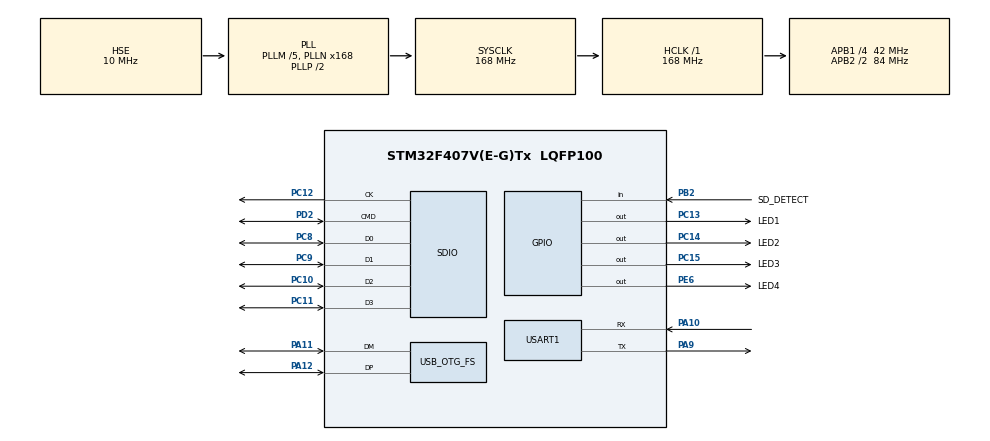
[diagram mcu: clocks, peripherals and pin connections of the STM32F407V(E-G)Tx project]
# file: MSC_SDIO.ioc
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Dma.Request0=SDIO_RX
Dma.Request1=SDIO_TX
Dma.SDIO_RX.0.Direction=DMA_PERIPH_TO_MEMORY
Dma.SDIO_RX.0.FIFOMode=DMA_FIFOMODE_ENABLE
Dma.SDIO_RX.0.FIFOThreshold=DMA_FIFO_THRESHOLD_FULL
Dma.SDIO_RX.0.Instance=DMA2_Stream3
Dma.SDIO_RX.0.MemBurst=DMA_MBURST_INC4
Dma.SDIO_RX.0.MemDataAlignment=DMA_MDATAALIGN_WORD
Dma.SDIO_RX.0.MemInc=DMA_MINC_ENABLE
Dma.SDIO_RX.0.Mode=DMA_PFCTRL
Dma.SDIO_RX.0.PeriphBurst=DMA_PBURST_INC4
Dma.SDIO_RX.0.PeriphDataAlignment=DMA_PDATAALIGN_WORD
Dma.SDIO_RX.0.PeriphInc=DMA_PINC_DISABLE
Dma.SDIO_RX.0.Priority=DMA_PRIORITY_LOW
Dma.SDIO_TX.1.Direction=DMA_MEMORY_TO_PERIPH
Dma.SDIO_TX.1.FIFOMode=DMA_FIFOMODE_ENABLE
Dma.SDIO_TX.1.FIFOThreshold=DMA_FIFO_THRESHOLD_FULL
Dma.SDIO_TX.1.Instance=DMA2_Stream6
Dma.SDIO_TX.1.MemBurst=DMA_MBURST_INC4
Dma.SDIO_TX.1.MemDataAlignment=DMA_MDATAALIGN_WORD
Dma.SDIO_TX.1.MemInc=DMA_MINC_ENABLE
Dma.SDIO_TX.1.Mode=DMA_PFCTRL
Dma.SDIO_TX.1.PeriphBurst=DMA_PBURST_INC4
Dma.SDIO_TX.1.PeriphDataAlignment=DMA_PDATAALIGN_WORD
Dma.SDIO_TX.1.PeriphInc=DMA_PINC_DISABLE
Dma.SDIO_TX.1.Priority=DMA_PRIORITY_LOW
FATFS.BSP.number=1
FATFS.USE_DMA_CODE_SD=1
FATFS._CODE_PAGE=936
FATFS._MAX_SS=4096
FATFS._USE_LABEL=1
FATFS._USE_LFN=2
FATFS0.BSP.STBoard=false
FATFS0.BSP.api=Unknown
FATFS0.BSP.instance=PB2
FATFS0.BSP.ip=GPIO
FATFS0.BSP.mode=Input
FATFS0.BSP.name=Detect_SDIO
FATFS0.BSP.solution=PB2
Mcu.Family=STM32F4
Mcu.Name=STM32F407V(E-G)Tx
Mcu.Package=LQFP100
NVIC.DMA2_Stream3_IRQn=true\:2\:0\:true\:false\:true\:false\:true\:true
NVIC.DMA2_Stream6_IRQn=true\:2\:0\:true\:false\:true\:false\:true\:true
NVIC.OTG_FS_IRQn=true\:0\:0\:true\:false\:true\:false\:true\:true
NVIC.PriorityGroup=NVIC_PRIORITYGROUP_4
NVIC.SDIO_IRQn=true\:0\:0\:true\:false\:true\:true\:true\:true
NVIC.USART1_IRQn=true\:0\:0\:true\:false\:true\:true\:true\:true
PA10.GPIO_Speed=GPIO_SPEED_FREQ_VERY_HIGH
PA10.Mode=Asynchronous
PA10.Signal=USART1_RX
PA11.GPIO_Speed=GPIO_SPEED_FREQ_VERY_HIGH
PA11.Mode=Device_Only
PA11.Signal=USB_OTG_FS_DM
PA12.GPIO_Speed=GPIO_SPEED_FREQ_VERY_HIGH
PA12.Mode=Device_Only
PA12.Signal=USB_OTG_FS_DP
PA13.Mode=Serial_Wire
PA13.Signal=SYS_JTMS-SWDIO
PA14.Mode=Serial_Wire
PA14.Signal=SYS_JTCK-SWCLK
PA9.GPIO_Speed=GPIO_SPEED_FREQ_VERY_HIGH
PA9.Mode=Asynchronous
PA9.Signal=USART1_TX
PB2.GPIO_Label=SD_DETECT
PB2.GPIO_PuPd=GPIO_PULLDOWN
PB2.Signal=GPIO_Input
PC10.GPIO_PuPd=GPIO_PULLUP
PC10.GPIO_Speed_High_Default=GPIO_SPEED_FREQ_HIGH
PC10.Mode=SD_4_bits_Wide_bus
PC10.Signal=SDIO_D2
PC11.GPIO_PuPd=GPIO_PULLUP
PC11.GPIO_Speed_High_Default=GPIO_SPEED_FREQ_HIGH
PC11.Mode=SD_4_bits_Wide_bus
PC11.Signal=SDIO_D3
PC12.GPIO_PuPd=GPIO_PULLUP
PC12.GPIO_Speed_High_Default=GPIO_SPEED_FREQ_HIGH
PC12.Mode=SD_4_bits_Wide_bus
PC12.Signal=SDIO_CK
PC13-ANTI_TAMP.GPIO_Label=LED1
PC13-ANTI_TAMP.PinState=GPIO_PIN_SET
PC13-ANTI_TAMP.Signal=GPIO_Output
PC14-OSC32_IN.GPIO_Label=LED2
PC14-OSC32_IN.PinState=GPIO_PIN_SET
PC14-OSC32_IN.Signal=GPIO_Output
PC15-OSC32_OUT.GPIO_Label=LED3
PC15-OSC32_OUT.PinState=GPIO_PIN_SET
PC15-OSC32_OUT.Signal=GPIO_Output
PC8.GPIO_PuPd=GPIO_PULLUP
PC8.GPIO_Speed_High_Default=GPIO_SPEED_FREQ_HIGH
PC8.Mode=SD_4_bits_Wide_bus
PC8.Signal=SDIO_D0
PC9.GPIO_PuPd=GPIO_PULLUP
PC9.GPIO_Speed_High_Default=GPIO_SPEED_FREQ_HIGH
PC9.Mode=SD_4_bits_Wide_bus
PC9.Signal=SDIO_D1
PD2.GPIO_PuPd=GPIO_PULLUP
PD2.GPIO_Speed_High_Default=GPIO_SPEED_FREQ_HIGH
PD2.Mode=SD_4_bits_Wide_bus
PD2.Signal=SDIO_CMD
PE6.GPIO_Label=LED4
PE6.PinState=GPIO_PIN_SET
PE6.Signal=GPIO_Output
PH0-OSC_IN.Mode=HSE-External-Oscillator
PH0-OSC_IN.Signal=RCC_OSC_IN
PH1-OSC_OUT.Mode=HSE-External-Oscillator
PH1-OSC_OUT.Signal=RCC_OSC_OUT
ProjectManager.HeapSize=0x800
ProjectManager.StackSize=0x1000
ProjectManager.TargetToolchain=STM32CubeIDE
RCC.48MHZClocksFreq_Value=48000000
RCC.AHBFreq_Value=168000000
RCC.APB1CLKDivider=RCC_HCLK_DIV4
RCC.APB1Freq_Value=42000000
RCC.APB1TimFreq_Value=84000000
RCC.APB2CLKDivider=RCC_HCLK_DIV2
RCC.APB2Freq_Value=84000000
RCC.APB2TimFreq_Value=168000000
RCC.CortexFreq_Value=168000000
RCC.EnbaleCSS=true
RCC.HCLKFreq_Value=168000000
RCC.HSE_VALUE=10000000
RCC.HSI_VALUE=16000000
RCC.LSE_VALUE=32768
RCC.PLLM=5
RCC.PLLN=168
RCC.PLLQ=7
RCC.SYSCLKFreq_VALUE=168000000
RCC.SYSCLKSource=RCC_SYSCLKSOURCE_PLLCLK
RCC.VCOOutputFreq_Value=336000000
SDIO.ClockDiv=40
SDIO.HardwareFlowControl=SDIO_HARDWARE_FLOW_CONTROL_ENABLE
USART1.VirtualMode=VM_ASYNC
USB_DEVICE.CLASS_NAME_FS=MSC
USB_DEVICE.CLASS_NAME_HS=MSC
USB_DEVICE.MSC_MEDIA_PACKET-MSC_FS=4096
USB_DEVICE.MSC_MEDIA_PACKET-MSC_HS=512
USB_DEVICE.VirtualMode-MSC_FS=Msc
USB_DEVICE.VirtualMode-MSC_HS=Msc
USB_DEVICE.VirtualModeFS=Msc_FS
USB_DEVICE.VirtualModeHS=Msc_HS
USB_OTG_FS.VirtualMode=Device_Only
VP_FATFS_VS_SDIO.Mode=SDIO
VP_USB_DEVICE_VS_USB_DEVICE_MSC_FS.Mode=MSC_FS
board=custom

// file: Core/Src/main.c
/* USER CODE BEGIN Header */
/**
  ******************************************************************************
  * @file           : main.c
  * @brief          : Main program body
  ******************************************************************************
  * @attention
  *
  * Copyright (c) 2024 STMicroelectronics.
  * All rights reserved.
  *
  * This software is licensed under terms that can be found in the LICENSE file
  * in the root directory of this software component.
  * If no LICENSE file comes with this software, it is provided AS-IS.
  *
  ******************************************************************************
  */
/* USER CODE END Header */
#include "main.h"
#include "fatfs.h"
#include "sdio.h"
#include "usart.h"
#include "usb_device.h"

/* USER CODE BEGIN Includes */
#include "dma.h"
#include "gpio.h"
/* USER CODE END Includes */

void SystemClock_Config(void);

/* USER CODE BEGIN 0 */
int _write(int file, char *ptr, int len)
{
  HAL_UART_Transmit(&huart1, (uint8_t*)ptr, len, HAL_MAX_DELAY);
  return len;
}
/* USER CODE END 0 */

int main(void)
{

  /* MCU Configuration--------------------------------------------------------*/

  /* Reset of all peripherals, Initializes the Flash interface and the Systick. */
  HAL_Init();

  /* Configure the system clock */
  SystemClock_Config();

  /* USER CODE BEGIN SysInit */
  MX_GPIO_Init();
  MX_DMA_Init();
  /* USER CODE END SysInit */

  /* Initialize all configured peripherals */
//  MX_USB_DEVICE_Init();
  MX_SDIO_SD_Init();
  MX_USART1_UART_Init();
  MX_FATFS_Init();
  /* USER CODE BEGIN 2 */
  MX_USB_DEVICE_Init();
  /* USER CODE END 2 */

  /* Infinite loop */
  while (1)
  {

  }
}

void SystemClock_Config(void)
{
  RCC_OscInitTypeDef RCC_OscInitStruct = {0};
  RCC_ClkInitTypeDef RCC_ClkInitStruct = {0};

  /** Configure the main internal regulator output voltage
  */
  __HAL_RCC_PWR_CLK_ENABLE();
  __HAL_PWR_VOLTAGESCALING_CONFIG(PWR_REGULATOR_VOLTAGE_SCALE1);

  /** Initializes the RCC Oscillators according to the specified parameters
  * in the RCC_OscInitTypeDef structure.
  */
  RCC_OscInitStruct.OscillatorType = RCC_OSCILLATORTYPE_HSE;
  RCC_OscInitStruct.HSEState = RCC_HSE_ON;
  RCC_OscInitStruct.PLL.PLLState = RCC_PLL_ON;
  RCC_OscInitStruct.PLL.PLLSource = RCC_PLLSOURCE_HSE;
  RCC_OscInitStruct.PLL.PLLM = 5;
  RCC_OscInitStruct.PLL.PLLN = 168;
  RCC_OscInitStruct.PLL.PLLP = RCC_PLLP_DIV2;
  RCC_OscInitStruct.PLL.PLLQ = 7;
  if (HAL_RCC_OscConfig(&RCC_OscInitStruct) != HAL_OK)
  {
    Error_Handler();
  }

  /** Initializes the CPU, AHB and APB buses clocks
  */
  RCC_ClkInitStruct.ClockType = RCC_CLOCKTYPE_HCLK|RCC_CLOCKTYPE_SYSCLK
                              |RCC_CLOCKTYPE_PCLK1|RCC_CLOCKTYPE_PCLK2;
  RCC_ClkInitStruct.SYSCLKSource = RCC_SYSCLKSOURCE_PLLCLK;
  RCC_ClkInitStruct.AHBCLKDivider = RCC_SYSCLK_DIV1;
  RCC_ClkInitStruct.APB1CLKDivider = RCC_HCLK_DIV4;
  RCC_ClkInitStruct.APB2CLKDivider = RCC_HCLK_DIV2;

  if (HAL_RCC_ClockConfig(&RCC_ClkInitStruct, FLASH_LATENCY_5) != HAL_OK)
  {
    Error_Handler();
  }

  /** Enables the Clock Security System
  */
  HAL_RCC_EnableCSS();
}

void Error_Handler(void)
{
  __disable_irq();
  while (1)
  {
  }
}
